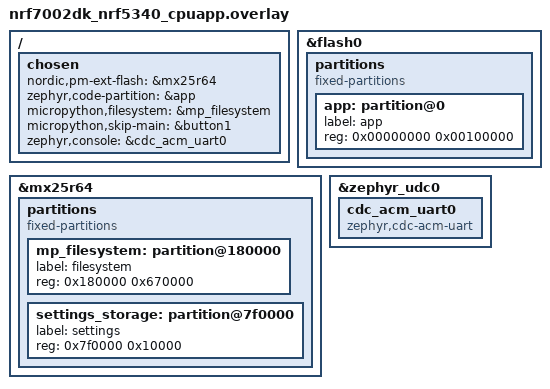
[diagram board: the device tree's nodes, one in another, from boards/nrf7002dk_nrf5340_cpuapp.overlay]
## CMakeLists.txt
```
# This file is part of the MicroPython project, http://micropython.org/
#
# The MIT License (MIT)
#
# Copyright 2020 NXP
#
# Permission is hereby granted, free of charge, to any person obtaining a copy
# of this software and associated documentation files (the "Software"), to deal
# in the Software without restriction, including without limitation the rights
# to use, copy, modify, merge, publish, distribute, sublicense, and/or sell
# copies of the Software, and to permit persons to whom the Software is
# furnished to do so, subject to the following conditions:
#
# The above copyright notice and this permission notice shall be included in
# all copies or substantial portions of the Software.
#
# THE SOFTWARE IS PROVIDED "AS IS", WITHOUT WARRANTY OF ANY KIND, EXPRESS OR
# IMPLIED, INCLUDING BUT NOT LIMITED TO THE WARRANTIES OF MERCHANTABILITY,
# FITNESS FOR A PARTICULAR PURPOSE AND NONINFRINGEMENT. IN NO EVENT SHALL THE
# AUTHORS OR COPYRIGHT HOLDERS BE LIABLE FOR ANY CLAIM, DAMAGES OR OTHER
# LIABILITY, WHETHER IN AN ACTION OF CONTRACT, TORT OR OTHERWISE, ARISING FROM,
# OUT OF OR IN CONNECTION WITH THE SOFTWARE OR THE USE OR OTHER DEALINGS IN
# THE SOFTWARE.

cmake_minimum_required(VERSION 3.20.0)

find_package(Zephyr REQUIRED HINTS $ENV{ZEPHYR_BASE})
project(micropython)

set(MICROPY_PORT_DIR    ${CMAKE_CURRENT_SOURCE_DIR})
set(MICROPY_DIR         ${MICROPY_PORT_DIR}/../..)
set(MICROPY_TARGET      micropython)

include(${MICROPY_DIR}/py/py.cmake)
include(${MICROPY_DIR}/extmod/extmod.cmake)

set(GEN_MACHINE_DEFS_SRC "${CMAKE_BINARY_DIR}/machine_defs.c")

set(MICROPY_SOURCE_PORT
    main.c
    help.c
    machine_i2c.c
    machine_spi.c
    machine_pin.c
    machine_uart.c
    modbluetooth_zephyr.c
    modmachine.c
    modsocket.c
    modzephyr.c
    modzsensor.c
    mphalport.c
    network_nrf91.c
    network_wlan.c
    uart_core.c
    zephyr_storage.c
)
list(TRANSFORM MICROPY_SOURCE_PORT PREPEND ${MICROPY_PORT_DIR}/)

list(APPEND MICROPY_SOURCE_PORT
    ${GEN_MACHINE_DEFS_SRC}
)

set(MICROPY_SOURCE_SHARED
    libc/printf.c
    readline/readline.c
    runtime/interrupt_char.c
    runtime/mpirq.c
    runtime/pyexec.c
    runtime/stdout_helpers.c
    timeutils/timeutils.c
)
list(TRANSFORM MICROPY_SOURCE_SHARED PREPEND ${MICROPY_DIR}/shared/)

set(MICROPY_SOURCE_LIB
    oofatfs/ff.c
    oofatfs/ffunicode.c
    littlefs/lfs1.c
    littlefs/lfs1_util.c
    littlefs/lfs2.c
    littlefs/lfs2_util.c
)
list(TRANSFORM MICROPY_SOURCE_LIB PREPEND ${MICROPY_DIR}/lib/)

set(MICROPY_SOURCE_QSTR
    ${MICROPY_SOURCE_PY}
    ${MICROPY_SOURCE_EXTMOD}
    ${MICROPY_SOURCE_SHARED}
    ${MICROPY_SOURCE_PORT}
)

zephyr_get_include_directories_for_lang(C includes)
zephyr_get_system_include_directories_for_lang(C system_includes)
zephyr_get_compile_definitions_for_lang(C definitions)
zephyr_get_compile_options_for_lang(C options)

set(MICROPY_CPP_FLAGS_EXTRA ${includes} ${system_includes} ${definitions} ${options})

zephyr_library_named(${MICROPY_TARGET})

zephyr_library_include_directories(
    ${MICROPY_INC_CORE}
    ${MICROPY_PORT_DIR}
    ${CMAKE_CURRENT_BINARY_DIR}
)

zephyr_library_compile_options(
    -std=gnu99 -fomit-frame-pointer
)

zephyr_library_compile_definitions(
    NDEBUG
    MP_CONFIGFILE=<${CONFIG_MICROPY_CONFIGFILE}>
    MICROPY_HEAP_SIZE=${CONFIG_MICROPY_HEAP_SIZE}
    FFCONF_H=\"${MICROPY_OOFATFS_DIR}/ffconf.h\"
    MICROPY_VFS_FAT=$<BOOL:${CONFIG_MICROPY_VFS_FAT}>
    MICROPY_VFS_LFS1=$<BOOL:${CONFIG_MICROPY_VFS_LFS1}>
    MICROPY_VFS_LFS2=$<BOOL:${CONFIG_MICROPY_VFS_LFS2}>
)

zephyr_library_sources(
    ${MICROPY_SOURCE_PY}
    ${MICROPY_SOURCE_EXTMOD}
    ${MICROPY_SOURCE_SHARED}
    ${MICROPY_SOURCE_LIB}
    ${MICROPY_SOURCE_PORT}
)

add_dependencies(${MICROPY_TARGET} zephyr_generated_headers)

include(${MICROPY_DIR}/py/mkrules.cmake)

set(GEN_MACHINE_DEFS_PY "${MICROPY_PORT_DIR}/make-machine-defs.py")
set(GEN_MACHINE_DEFS_PREFIX "${MICROPY_PORT_DIR}/machine_prefix.c")
set(GEN_MACHINE_DEFS_HDR "${MICROPY_GENHDR_DIR}/machine_defs.h")
set(GEN_MACHINE_DEFS_EDT_PICKLE "${CMAKE_BINARY_DIR}/zephyr/edt.pickle")

add_custom_command(
    OUTPUT ${GEN_MACHINE_DEFS_HDR} ${GEN_MACHINE_DEFS_SRC}
    COMMAND ${Python3_EXECUTABLE} ${GEN_MACHINE_DEFS_PY} --prefix ${GEN_MACHINE_DEFS_PREFIX} --output-source ${GEN_MACHINE_DEFS_SRC} --output-header ${GEN_MACHINE_DEFS_HDR} --edt-pickle ${GEN_MACHINE_DEFS_EDT_PICKLE}
    DEPENDS
        ${GEN_MACHINE_DEFS_PY}
        ${GEN_MACHINE_DEFS_PREFIX}
        ${GEN_MACHINE_DEFS_EDT_PICKLE}
        ${MICROPY_MPVERSION}
    VERBATIM
    COMMAND_EXPAND_LISTS
)

target_sources(app PRIVATE
    src/zephyr_start.c
    src/zephyr_getchar.c
)

target_link_libraries(app PRIVATE ${MICROPY_TARGET})
```

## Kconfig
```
# This file is part of the MicroPython project, http://micropython.org/
#
# The MIT License (MIT)
#
# Copyright 2020 NXP
#
# Permission is hereby granted, free of charge, to any person obtaining a copy
# of this software and associated documentation files (the "Software"), to deal
# in the Software without restriction, including without limitation the rights
# to use, copy, modify, merge, publish, distribute, sublicense, and/or sell
# copies of the Software, and to permit persons to whom the Software is
# furnished to do so, subject to the following conditions:
#
# The above copyright notice and this permission notice shall be included in
# all copies or substantial portions of the Software.
#
# THE SOFTWARE IS PROVIDED "AS IS", WITHOUT WARRANTY OF ANY KIND, EXPRESS OR
# IMPLIED, INCLUDING BUT NOT LIMITED TO THE WARRANTIES OF MERCHANTABILITY,
# FITNESS FOR A PARTICULAR PURPOSE AND NONINFRINGEMENT. IN NO EVENT SHALL THE
# AUTHORS OR COPYRIGHT HOLDERS BE LIABLE FOR ANY CLAIM, DAMAGES OR OTHER
# LIABILITY, WHETHER IN AN ACTION OF CONTRACT, TORT OR OTHERWISE, ARISING FROM,
# OUT OF OR IN CONNECTION WITH THE SOFTWARE OR THE USE OR OTHER DEALINGS IN
# THE SOFTWARE.

menu "MicroPython Options"

config MICROPY_CONFIGFILE
	string "Configuration file"
	default "mpconfigport_minimal.h"

config MICROPY_HEAP_SIZE
	int "Heap size"
	default 16384

config MICROPY_VFS_FAT
	bool "FatFS file system"

config MICROPY_VFS_LFS1
	bool "LittleFs version 1 file system"

config MICROPY_VFS_LFS2
	bool "LittleFs version 2 file system"

config MICROPY_NRF91_LOCATION
	bool "Include nRF91 Location services"
	default n
	imply LOCATION
	imply LOCATION_METHOD_GNSS
	imply LOCATION_METHOD_CELLULAR
	imply LOCATION_DATA_DETAILS
	imply LOCATION_SERVICE_EXTERNAL
	imply NRF_CLOUD_AGNSS
	imply MODEM_INFO
	imply MODEM_INFO_ADD_NETWORK

config EXCLUDE_PY_SOCKETS
	bool "Don't include socket module"
	default n

endmenu # MicroPython Options

source "Kconfig.zephyr"
```

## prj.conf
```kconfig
CONFIG_BUILD_OUTPUT_BIN=y
CONFIG_BUILD_OUTPUT_HEX=y
CONFIG_REBOOT=y

CONFIG_STDOUT_CONSOLE=y
CONFIG_CONSOLE_HANDLER=y
CONFIG_UART_CONSOLE_DEBUG_SERVER_HOOKS=y

CONFIG_CONSOLE_SUBSYS=n

CONFIG_NEWLIB_LIBC=y
CONFIG_FPU=y
CONFIG_MAIN_STACK_SIZE=4736
CONFIG_POLL=y

# Enable sensor subsystem (doesn't add code if not used).
# Specific sensors should be enabled per-board.
CONFIG_SENSOR=y

# Hardware features
CONFIG_I2C=y
CONFIG_SPI=y

# Diagnostics and debugging

# Required for zephyr.stack_analyze()
CONFIG_THREAD_ANALYZER=y
CONFIG_THREAD_ANALYZER_USE_PRINTK=y
CONFIG_THREAD_NAME=y

# Required for socket.pkt_get_info()
CONFIG_NET_BUF_POOL_USAGE=y

# MicroPython options
CONFIG_MICROPY_CONFIGFILE="mpconfigport.h"
CONFIG_MICROPY_VFS_LFS2=y
```

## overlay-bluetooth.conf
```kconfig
CONFIG_BT=y
CONFIG_BT_DEVICE_NAME_DYNAMIC=y
CONFIG_BT_PERIPHERAL=y
CONFIG_BT_CENTRAL=y
CONFIG_BT_GATT_DYNAMIC_DB=y
CONFIG_BT_SMP=y
```

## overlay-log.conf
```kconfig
CONFIG_LOG=y
CONFIG_LOG_PRINTK=y
CONFIG_USE_SEGGER_RTT=y
CONFIG_LOG_BACKEND_RTT=y
CONFIG_LOG_BACKEND_UART=n
CONFIG_LOG_BUFFER_SIZE=2048
CONFIG_BT_GATT_LOG_LEVEL_DBG=y
```

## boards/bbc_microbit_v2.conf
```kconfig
CONFIG_CONSOLE_SUBSYS=n
CONFIG_NETWORKING=n

CONFIG_MICROPY_HEAP_SIZE=98304

# Include overlay-bluetooth.conf in build to add Bluetooth support
```

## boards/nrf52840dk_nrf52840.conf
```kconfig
# Hardware features
CONFIG_I2C=y
CONFIG_SPI=y

# Flash drivers
CONFIG_FLASH=y
CONFIG_FLASH_MAP=y
CONFIG_FLASH_PAGE_LAYOUT=y

CONFIG_BT=y
CONFIG_BT_DEVICE_NAME_DYNAMIC=y
CONFIG_BT_PERIPHERAL=y
CONFIG_BT_CENTRAL=y

# System settings
CONFIG_NEWLIB_LIBC=y
CONFIG_NEWLIB_LIBC_NANO=n

# Memories
CONFIG_MAIN_STACK_SIZE=4096
CONFIG_SYSTEM_WORKQUEUE_STACK_SIZE=2048
CONFIG_NET_TX_STACK_SIZE=4096
CONFIG_NET_RX_STACK_SIZE=4096


# Kernel options
CONFIG_ENTROPY_GENERATOR=y

# Logging
CONFIG_LOG=y
CONFIG_LOG_PRINTK=y
CONFIG_USE_SEGGER_RTT=y
CONFIG_LOG_BACKEND_RTT=y
CONFIG_LOG_BACKEND_UART=n
CONFIG_LOG_BUFFER_SIZE=2048
CONFIG_POSIX_CLOCK=y

CONFIG_PM=y

CONFIG_BT_GATT_DYNAMIC_DB=y
CONFIG_BT_DEBUG_LOG=y
CONFIG_BT_GATT_LOG_LEVEL_DBG=y
```

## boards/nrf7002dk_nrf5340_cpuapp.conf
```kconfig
# Hardware features
CONFIG_I2C=y
CONFIG_SPI=y

CONFIG_BOOTLOADER_MCUBOOT=y

# Flash drivers
CONFIG_FLASH=y
CONFIG_FLASH_MAP=y
CONFIG_FLASH_PAGE_LAYOUT=y

CONFIG_SPI_NOR=y
CONFIG_SPI_NOR_FLASH_LAYOUT_PAGE_SIZE=4096
CONFIG_PM_OVERRIDE_EXTERNAL_DRIVER_CHECK=y
CONFIG_PM_EXTERNAL_FLASH_MCUBOOT_SECONDARY=y
CONFIG_NRF53_UPGRADE_NETWORK_CORE=y

CONFIG_WIFI=y
CONFIG_WIFI_NRF700X=y

CONFIG_NVS=y
CONFIG_SETTINGS=y
CONFIG_SETTINGS_NVS=y
CONFIG_WIFI_CREDENTIALS=y
CONFIG_WIFI_CREDENTIALS_BACKEND_SETTINGS=y

# USB REPL
CONFIG_USB_DEVICE_STACK=y
CONFIG_USB_DEVICE_PRODUCT="Micropython REPL"
CONFIG_USB_DEVICE_PID=0x53AA
CONFIG_USB_DEVICE_VID=0x1915
CONFIG_USB_DEVICE_INITIALIZE_AT_BOOT=n

# WPA supplicant
CONFIG_WPA_SUPP=y

# System settings
CONFIG_NEWLIB_LIBC=y
CONFIG_NEWLIB_LIBC_NANO=n

# Networking
CONFIG_NETWORKING=y
CONFIG_NET_IPV4=y
CONFIG_NET_IPV6=y
CONFIG_NET_UDP=y
CONFIG_NET_TCP=y
CONFIG_NET_SOCKETS=y
CONFIG_TEST_RANDOM_GENERATOR=y

CONFIG_NET_CONFIG_INIT_TIMEOUT=0
CONFIG_NET_CONFIG_NEED_IPV6=y
CONFIG_NET_CONFIG_NEED_IPV4=y

# DNS
CONFIG_DNS_RESOLVER=y
CONFIG_DNS_RESOLVER_ADDITIONAL_QUERIES=2
CONFIG_DNS_SERVER_IP_ADDRESSES=y

CONFIG_NET_DHCPV4=y
CONFIG_POSIX_API=n
CONFIG_NET_SOCKETS_POSIX_NAMES=y

CONFIG_NET_PKT_RX_COUNT=6
CONFIG_NET_PKT_TX_COUNT=6

# Memories
CONFIG_MAIN_STACK_SIZE=20480
CONFIG_SYSTEM_WORKQUEUE_STACK_SIZE=2048
CONFIG_NET_TX_STACK_SIZE=4096
CONFIG_NET_RX_STACK_SIZE=4096
CONFIG_MICROPY_HEAP_SIZE=98304


# Below section is the primary contributor to SRAM
CONFIG_NET_BUF_RX_COUNT=6
CONFIG_NET_BUF_TX_COUNT=12
CONFIG_NET_BUF_DATA_SIZE=128
CONFIG_HEAP_MEM_POOL_SIZE=153600
CONFIG_NET_TC_TX_COUNT=0

CONFIG_NET_IF_UNICAST_IPV4_ADDR_COUNT=1
CONFIG_NET_MAX_CONTEXTS=5
CONFIG_NET_CONTEXT_SYNC_RECV=y

CONFIG_INIT_STACKS=y

CONFIG_NET_L2_ETHERNET=y

CONFIG_NET_SOCKETS_POLL_MAX=6

# Kernel options
CONFIG_ENTROPY_GENERATOR=y

# Logging
CONFIG_LOG=n

CONFIG_POSIX_CLOCK=y

CONFIG_NET_MGMT_EVENT_STACK_SIZE=2048

CONFIG_NET_MGMT_EVENT_INFO=y
```

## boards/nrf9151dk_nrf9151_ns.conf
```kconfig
# General config
CONFIG_NEWLIB_LIBC=y
CONFIG_NEWLIB_LIBC_FLOAT_PRINTF=y
CONFIG_ASSERT=y
CONFIG_REBOOT=y
CONFIG_FPU=y

# Heap and stacks
CONFIG_HEAP_MEM_POOL_SIZE=16384
CONFIG_MAIN_STACK_SIZE=20480
CONFIG_SYSTEM_WORKQUEUE_STACK_SIZE=4096
CONFIG_HW_STACK_PROTECTION=y
CONFIG_MICROPY_HEAP_SIZE=98304
CONFIG_AT_MONITOR_HEAP_SIZE=2048

# MCUBOOT
CONFIG_BOOTLOADER_MCUBOOT=y
CONFIG_IMG_MANAGER=y
CONFIG_STREAM_FLASH=y
CONFIG_DEBUG_OPTIMIZATIONS=n
CONFIG_TFM_CMAKE_BUILD_TYPE_DEBUG=n

# Hardware features
CONFIG_I2C=y
CONFIG_SPI=y

# Flash drivers
CONFIG_FLASH=y
CONFIG_FLASH_MAP=y
CONFIG_FLASH_PAGE_LAYOUT=y
CONFIG_STREAM_FLASH_ERASE=y

# Network (offload sockets to the modem)
CONFIG_NETWORKING=y
CONFIG_NET_SOCKETS=y
CONFIG_NET_SOCKETS_POSIX_NAMES=y
CONFIG_NET_PKT_RX_COUNT=8
CONFIG_NET_PKT_TX_COUNT=8
CONFIG_NET_NATIVE=n
CONFIG_DNS_RESOLVER=n
CONFIG_NET_CONFIG_NEED_IPV6=y
CONFIG_NET_CONFIG_NEED_IPV4=y
CONFIG_NET_DHCPV4=n

CONFIG_POSIX_CLOCK=y

CONFIG_LTE_LINK_CONTROL=y
CONFIG_NRF_MODEM_LIB=y
CONFIG_PM_DEVICE=y
CONFIG_PDN=y

# Enable external flash
CONFIG_SPI=y
CONFIG_SPI_NOR=y
CONFIG_SPI_NOR_SFDP_DEVICETREE=y
CONFIG_PM_OVERRIDE_EXTERNAL_DRIVER_CHECK=y

CONFIG_MICROPY_NRF91_LOCATION=y

# Library that maintains the current date time UTC for A-GNSS and P-GPS purposes
CONFIG_DATE_TIME=y

# Modem JWT
CONFIG_MODEM_JWT=y

#CONFIG_NRF_MODEM_LIB_TRACE=y
```

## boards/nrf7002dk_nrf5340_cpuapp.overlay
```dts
/*
 * Copyright (c) 2023 Mariano Goluboff
 *
 * SPDX-License-Identifier: Apache-2.0
 */

 / {
	chosen {
		nordic,pm-ext-flash = &mx25r64;
		zephyr,code-partition = &app;
		micropython,filesystem = &mp_filesystem;
		micropython,skip-main = &button1;
		zephyr,console = &cdc_acm_uart0;
	};
};

 /delete-node/ &boot_partition;
 /delete-node/ &slot0_partition;
 /delete-node/ &slot0_ns_partition;
 /delete-node/ &slot1_partition;
 /delete-node/ &slot1_ns_partition;
 /delete-node/ &scratch_partition;
 /delete-node/ &storage_partition;
 
 &flash0 {
	partitions {
		compatible = "fixed-partitions";
		#address-cells = <1>;
		#size-cells = <1>;

		app: partition@0 {
			label = "app";
			reg = <0x00000000 0x00100000>;
		};
	};
};

 &mx25r64 {
	partitions {
		compatible = "fixed-partitions";
		#address-cells = <1>;
		#size-cells = <1>;

		mp_filesystem: partition@180000 {
			label = "filesystem";
			reg = <0x180000 0x670000>;
		};
		settings_storage: partition@7f0000 {
			label = "settings";
			reg = <0x7f0000 0x10000>;
		};
	};
};

&zephyr_udc0 {
	cdc_acm_uart0: cdc_acm_uart0 {
		compatible = "zephyr,cdc-acm-uart";
	};
};
```

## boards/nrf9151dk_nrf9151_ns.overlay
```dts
/ {
	chosen {
		nordic,pm-ext-flash = &gd25wb256;
		micropython,skip-main = &button1;
	};
};

&gd25wb256 {
	status = "okay";
};

&gpio0 {
	sense-edge-mask = < 0xffffffff >;
};
```

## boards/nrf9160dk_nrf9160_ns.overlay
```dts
/ {
	chosen {
		nordic,pm-ext-flash = &mx25r64;
		micropython,skip-main = &button1;
	};
};

&mx25r64 {
	status = "okay";
};
```

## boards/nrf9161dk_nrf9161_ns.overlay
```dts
/ {
	chosen {
		nordic,pm-ext-flash = &gd25wb256;
		micropython,skip-main = &button1;
	};
};

&gd25wb256 {
	status = "okay";
};
```

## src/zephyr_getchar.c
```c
/*
 * Copyright (c) 2016 Linaro
 *
 * Licensed under the Apache License, Version 2.0 (the "License");
 * you may not use this file except in compliance with the License.
 * You may obtain a copy of the License at
 *
 *     http://www.apache.org/licenses/LICENSE-2.0
 *
 * Unless required by applicable law or agreed to in writing, software
 * distributed under the License is distributed on an "AS IS" BASIS,
 * WITHOUT WARRANTIES OR CONDITIONS OF ANY KIND, either express or implied.
 * See the License for the specific language governing permissions and
 * limitations under the License.
 */

#include <zephyr/kernel.h>
#include <zephyr/drivers/uart.h>
#include <zephyr/drivers/console/uart_console.h>
#include <zephyr/sys/printk.h>
#include "zephyr_getchar.h"

extern int mp_interrupt_char;
void mp_sched_keyboard_interrupt(void);
void mp_hal_signal_event(void);
void mp_hal_wait_sem(struct k_sem *sem, uint32_t timeout_ms);

static struct k_sem uart_sem;
#define UART_BUFSIZE 256
static uint8_t uart_ringbuf[UART_BUFSIZE];
static uint8_t i_get, i_put, i_size;

static int console_irq_input_hook(uint8_t ch) {
    int i_next = (i_put + 1) & (UART_BUFSIZE - 1);
    if (i_next == i_get) {
        printk("UART buffer overflow - char dropped\n");
        return 1;
    }
    if (ch == mp_interrupt_char) {
        mp_hal_signal_event();
        mp_sched_keyboard_interrupt();
        return 1;
    } else {
        uart_ringbuf[i_put] = ch;
        i_put = i_next;
        i_size++;
    }
    // printk("%x\n", ch);
    k_sem_give(&uart_sem);
    // Try to avoid buffer overflows
    if (i_size > (UART_BUFSIZE - 50)) {
        k_msleep(1);
    }
    return 1;
}

uint8_t zephyr_getchar(void) {
    uint8_t c;

    while (zephyr_getchar_timeout(-1, &c) != 0) { }
    return c;
}

int zephyr_getchar_timeout(uint32_t timeout, uint8_t *c) {
    mp_hal_wait_sem(&uart_sem, timeout);
    if (k_sem_take(&uart_sem, K_NO_WAIT) != 0) {
        return -ENODEV;
    }
    unsigned int key = irq_lock();
    *c = uart_ringbuf[i_get++];
    i_get &= UART_BUFSIZE - 1;
    i_size--;
    irq_unlock(key);
    return 0;
}

void zephyr_getchar_init(void) {
    k_sem_init(&uart_sem, 0, UINT_MAX);
    uart_console_in_debug_hook_install(console_irq_input_hook);
    // All NULLs because we're interested only in the callback above
    uart_register_input(NULL, NULL, NULL);
}
```

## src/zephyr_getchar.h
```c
/*
 * Copyright (c) 2016 Linaro
 *
 * Licensed under the Apache License, Version 2.0 (the "License");
 * you may not use this file except in compliance with the License.
 * You may obtain a copy of the License at
 *
 *     http://www.apache.org/licenses/LICENSE-2.0
 *
 * Unless required by applicable law or agreed to in writing, software
 * distributed under the License is distributed on an "AS IS" BASIS,
 * WITHOUT WARRANTIES OR CONDITIONS OF ANY KIND, either express or implied.
 * See the License for the specific language governing permissions and
 * limitations under the License.
 */

#include <stdint.h>

void zephyr_getchar_init(void);
uint8_t zephyr_getchar(void);
int zephyr_getchar_timeout(uint32_t timeout, uint8_t *c);
```
